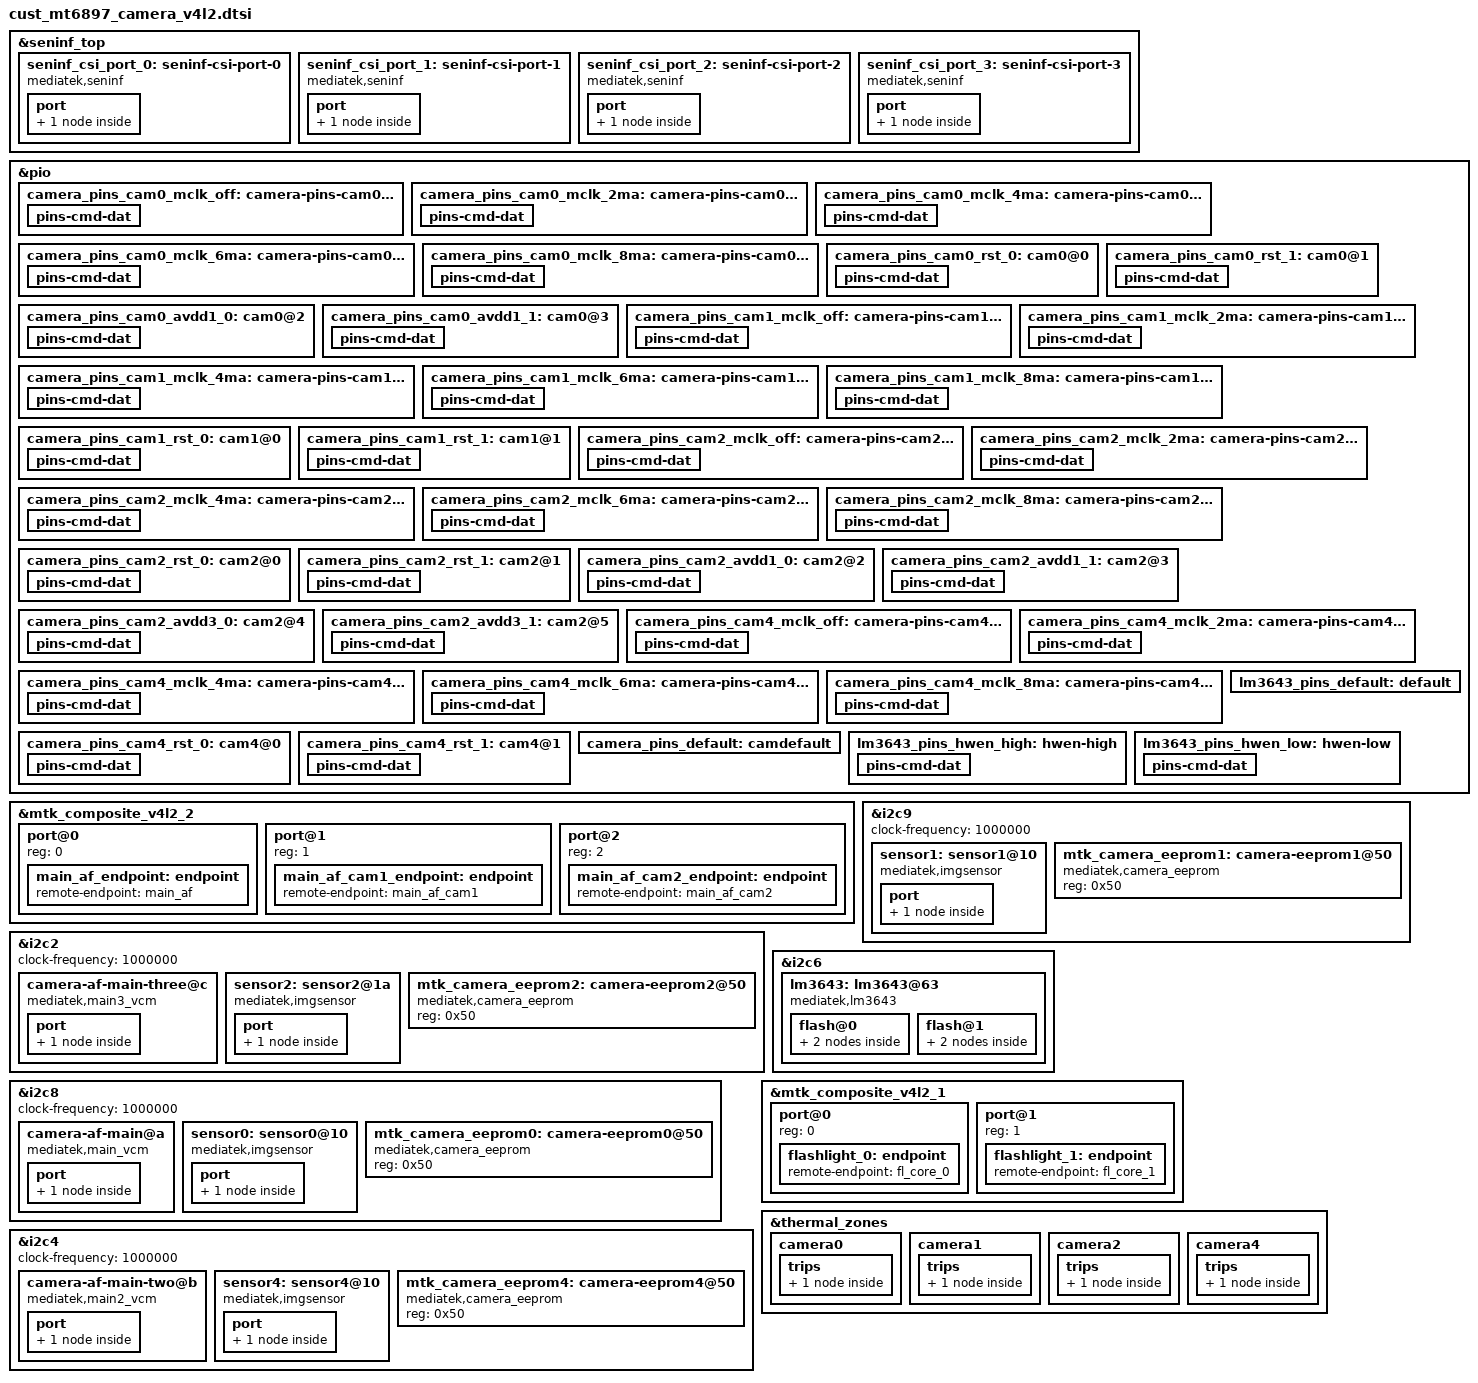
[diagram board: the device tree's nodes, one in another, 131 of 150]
// SPDX-License-Identifier: GPL-2.0
/* Copyright (c) 2020 MediaTek Inc. */
#include <dt-bindings/clock/mt6897-clk.h>


&seninf_top {
		seninf_csi_port_0: seninf-csi-port-0 {
			compatible = "mediatek,seninf";
			csi-port = "0";
			dphy-settle-delay-dt = <17>;
			nvmem-cells = <&csi_efuse0>;
			nvmem-cell-names = "rg_csi";
			port {
				seninf_csi_port_0_in: endpoint {
					remote-endpoint = <&sensor1_out>;
				};
			};
		};

		seninf_csi_port_1: seninf-csi-port-1 {
			compatible = "mediatek,seninf";
			csi-port = "1";
			hs-trail-parameter = <0x20>;
			nvmem-cells = <&csi_efuse1>;
			nvmem-cell-names = "rg_csi";
			port {
				seninf_csi_port_1_in: endpoint {
					remote-endpoint = <&sensor4_out>;
				};
			};
		};

		seninf_csi_port_2: seninf-csi-port-2 {
			compatible = "mediatek,seninf";
			csi-port = "2";
			hs-trail-parameter = <0x20>;
			nvmem-cells = <&csi_efuse2>;
			nvmem-cell-names = "rg_csi";
			port {
				seninf_csi_port_2_in: endpoint {
					remote-endpoint = <&sensor0_out>;
				};
			};
		};
		seninf_csi_port_3: seninf-csi-port-3 {
			compatible = "mediatek,seninf";
			csi-port = "3";
			nvmem-cells = <&csi_efuse3>;
			nvmem-cell-names = "rg_csi";
			port {
				seninf_csi_port_3_in: endpoint {
					remote-endpoint = <&sensor2_out>;
				};
			};
		};
};

/* CAMERA GPIO standardization */
&pio {
	camera_pins_cam0_mclk_off: camera-pins-cam0-mclk-off {
		pins-cmd-dat {
			pinmux = <PINMUX_GPIO125__FUNC_GPIO125>;
			drive-strength = <1>;
		};
	};
	camera_pins_cam0_mclk_2ma: camera-pins-cam0-mclk-2ma {
		pins-cmd-dat {
			pinmux = <PINMUX_GPIO125__FUNC_CMMCLK2>;
			drive-strength = <0>;
		};
	};
	camera_pins_cam0_mclk_4ma: camera-pins-cam0-mclk-4ma {
		pins-cmd-dat {
			pinmux = <PINMUX_GPIO125__FUNC_CMMCLK2>;
			drive-strength = <1>;
		};
	};
	camera_pins_cam0_mclk_6ma: camera-pins-cam0-mclk-6ma {
		pins-cmd-dat {
			pinmux = <PINMUX_GPIO125__FUNC_CMMCLK2>;
			drive-strength = <2>;
		};
	};
	camera_pins_cam0_mclk_8ma: camera-pins-cam0-mclk-8ma {
		pins-cmd-dat {
			pinmux = <PINMUX_GPIO125__FUNC_CMMCLK2>;
			drive-strength = <3>;
		};
	};
	camera_pins_cam0_rst_0: cam0@0 {
		pins-cmd-dat {
			pinmux = <PINMUX_GPIO117__FUNC_GPIO117>;
			slew-rate = <1>;
			output-low;
		};
	};
	camera_pins_cam0_rst_1: cam0@1 {
		pins-cmd-dat {
			pinmux = <PINMUX_GPIO117__FUNC_GPIO117>;
			slew-rate = <1>;
			output-high;
		};
	};
	camera_pins_cam0_avdd1_0: cam0@2 {
		pins-cmd-dat {
			pinmux = <PINMUX_GPIO160__FUNC_GPIO160>;
			slew-rate = <1>;
			output-low;
		};
	};
	camera_pins_cam0_avdd1_1: cam0@3 {
		pins-cmd-dat {
			pinmux = <PINMUX_GPIO160__FUNC_GPIO160>;
			slew-rate = <1>;
			output-high;
		};
	};
	camera_pins_cam1_mclk_off: camera-pins-cam1-mclk-off {
		pins-cmd-dat {
			pinmux = <PINMUX_GPIO126__FUNC_GPIO126>;
			drive-strength = <1>;
		};
	};
	camera_pins_cam1_mclk_2ma: camera-pins-cam1-mclk-2ma {
		pins-cmd-dat {
			pinmux = <PINMUX_GPIO126__FUNC_CMMCLK3>;
			drive-strength = <0>;
		};
	};
	camera_pins_cam1_mclk_4ma: camera-pins-cam1-mclk-4ma {
		pins-cmd-dat {
			pinmux = <PINMUX_GPIO126__FUNC_CMMCLK3>;
			drive-strength = <1>;
		};
	};
	camera_pins_cam1_mclk_6ma: camera-pins-cam1-mclk-6ma {
		pins-cmd-dat {
			pinmux = <PINMUX_GPIO126__FUNC_CMMCLK3>;
			drive-strength = <2>;
		};
	};
	camera_pins_cam1_mclk_8ma: camera-pins-cam1-mclk-8ma {
		pins-cmd-dat {
			pinmux = <PINMUX_GPIO126__FUNC_CMMCLK3>;
			drive-strength = <3>;
		};
	};
	camera_pins_cam1_rst_0: cam1@0 {
		pins-cmd-dat {
			pinmux = <PINMUX_GPIO118__FUNC_GPIO118>;
			slew-rate = <1>;
			output-low;
		};
	};
	camera_pins_cam1_rst_1: cam1@1 {
		pins-cmd-dat {
			pinmux = <PINMUX_GPIO118__FUNC_GPIO118>;
			slew-rate = <1>;
			output-high;
		};
	};
	camera_pins_cam2_mclk_off: camera-pins-cam2-mclk-off {
		pins-cmd-dat {
			pinmux = <PINMUX_GPIO127__FUNC_GPIO127>;
			drive-strength = <1>;
		};
	};
	camera_pins_cam2_mclk_2ma: camera-pins-cam2-mclk-2ma {
		pins-cmd-dat {
			pinmux = <PINMUX_GPIO127__FUNC_CMMCLK4>;
			drive-strength = <0>;
		};
	};
	camera_pins_cam2_mclk_4ma: camera-pins-cam2-mclk-4ma {
		pins-cmd-dat {
			pinmux = <PINMUX_GPIO127__FUNC_CMMCLK4>;
			drive-strength = <1>;
		};
	};
	camera_pins_cam2_mclk_6ma: camera-pins-cam2-mclk-6ma {
		pins-cmd-dat {
			pinmux = <PINMUX_GPIO127__FUNC_CMMCLK4>;
			drive-strength = <2>;
		};
	};
	camera_pins_cam2_mclk_8ma: camera-pins-cam2-mclk-8ma {
		pins-cmd-dat {
			pinmux = <PINMUX_GPIO127__FUNC_CMMCLK4>;
			drive-strength = <3>;
		};
	};
	camera_pins_cam2_rst_0: cam2@0 {
		pins-cmd-dat {
			pinmux = <PINMUX_GPIO115__FUNC_GPIO115>;
			slew-rate = <1>;
			output-low;
		};
	};
	camera_pins_cam2_rst_1: cam2@1 {
		pins-cmd-dat {
			pinmux = <PINMUX_GPIO115__FUNC_GPIO115>;
			slew-rate = <1>;
			output-high;
		};
	};
	camera_pins_cam2_avdd1_0: cam2@2 {
		pins-cmd-dat {
			pinmux = <PINMUX_GPIO120__FUNC_GPIO120>;
			slew-rate = <1>;
			output-low;
		};
	};

	camera_pins_cam2_avdd1_1: cam2@3 {
		pins-cmd-dat {
			pinmux = <PINMUX_GPIO120__FUNC_GPIO120>;
			slew-rate = <1>;
			output-high;
		};
	};

	camera_pins_cam2_avdd3_0: cam2@4 {
		pins-cmd-dat {
			pinmux = <PINMUX_GPIO134__FUNC_GPIO134>;
			slew-rate = <1>;
			output-low;
		};
	};
	camera_pins_cam2_avdd3_1: cam2@5 {
		pins-cmd-dat {
			pinmux = <PINMUX_GPIO134__FUNC_GPIO134>;
			slew-rate = <1>;
			output-high;
		};
	};

	camera_pins_cam4_mclk_off: camera-pins-cam4-mclk-off {
		pins-cmd-dat {
			pinmux = <PINMUX_GPIO124__FUNC_GPIO124>;
			drive-strength = <1>;
		};
	};
	camera_pins_cam4_mclk_2ma: camera-pins-cam4-mclk-2ma {
		pins-cmd-dat {
			pinmux = <PINMUX_GPIO124__FUNC_CMMCLK1>;
			drive-strength = <0>;
		};
	};
	camera_pins_cam4_mclk_4ma: camera-pins-cam4-mclk-4ma {
		pins-cmd-dat {
			pinmux = <PINMUX_GPIO124__FUNC_CMMCLK1>;
			drive-strength = <1>;
		};
	};
	camera_pins_cam4_mclk_6ma: camera-pins-cam4-mclk-6ma {
		pins-cmd-dat {
			pinmux = <PINMUX_GPIO124__FUNC_CMMCLK1>;
			drive-strength = <2>;
		};
	};
	camera_pins_cam4_mclk_8ma: camera-pins-cam4-mclk-8ma {
		pins-cmd-dat {
			pinmux = <PINMUX_GPIO124__FUNC_CMMCLK1>;
			drive-strength = <3>;
		};
	};
	camera_pins_cam4_rst_0: cam4@0 {
		pins-cmd-dat {
			pinmux = <PINMUX_GPIO116__FUNC_GPIO116>;
			slew-rate = <1>;
			output-low;
		};
	};
	camera_pins_cam4_rst_1: cam4@1 {
		pins-cmd-dat {
			pinmux = <PINMUX_GPIO116__FUNC_GPIO116>;
			slew-rate = <1>;
			output-high;
		};
	};
	camera_pins_default: camdefault {
	};
};
/* CAMERA GPIO end */

&mtk_composite_v4l2_2 {
	#address-cells = <1>;
	#size-cells = <0>;
	port@0 {
		reg = <0>;
		main_af_endpoint: endpoint {
			remote-endpoint = <&main_af>;
		};
	};
	port@1 {
		reg = <1>;
		main_af_cam1_endpoint: endpoint {
			remote-endpoint = <&main_af_cam1>;
		};
	};
	port@2 {
		reg = <2>;
		main_af_cam2_endpoint: endpoint {
			remote-endpoint = <&main_af_cam2>;
		};
	};
};

&i2c2 {
	status = "okay";
	clock-frequency = <1000000>;
	#address-cells = <1>;
	#size-cells = <0>;

	camera-af-main-three@c {
		compatible = "mediatek,main3_vcm";
		reg = <0x0c>;
		vin-supply = <&rt5133_gpio1>;
		port {
			main_af_cam2: endpoint {
				remote-endpoint = <&main_af_cam2_endpoint>;
			};
		};
	};

	sensor2: sensor2@1a {
		compatible = "mediatek,imgsensor";
		sensor-names = "imx766_mipi_raw",
				"imx709_mipi_raw",
				"imx866_mipi_raw",
				"imx598_mipi_raw";
		reg = <0x1a>;
		#thermal-sensor-cells = <0>;

		reindex-match = "imx766_mipi_raw",
				"imx709_mipi_raw",
				"imx866_mipi_raw";

		reindex-to = <0>;

		pinctrl-names = "mclk_off",
				"mclk_2mA",
				"mclk_4mA",
				"mclk_6mA",
				"mclk_8mA",
				"rst_low",
				"rst_high",
				"avdd1_off",
				"avdd1_on",
				"avdd3_off",
				"avdd3_on";
		pinctrl-0 = <&camera_pins_cam2_mclk_off>;
		pinctrl-1 = <&camera_pins_cam2_mclk_2ma>;
		pinctrl-2 = <&camera_pins_cam2_mclk_4ma>;
		pinctrl-3 = <&camera_pins_cam2_mclk_6ma>;
		pinctrl-4 = <&camera_pins_cam2_mclk_8ma>;
		pinctrl-5 = <&camera_pins_cam2_rst_0>;
		pinctrl-6 = <&camera_pins_cam2_rst_1>;
		pinctrl-7 = <&camera_pins_cam2_avdd1_0>; // AVDD2 for imx766
		pinctrl-8 = <&camera_pins_cam2_avdd1_1>; // AVDD2 for imx766
		pinctrl-9 = <&camera_pins_cam2_avdd3_0>; // AVDD2 for imx866
		pinctrl-10 = <&camera_pins_cam2_avdd3_1>; // AVDD2 for imx866

		avdd4-supply = <&rt5133_ldo5>; // AVDD2 for imx598
		avdd2-supply = <&rt5133_gpio2>; // AVDD for imx766 & imx866
		dvdd-supply = <&rt5133_ldo7>;
		dovdd-supply = <&rt5133_ldo1>;
		afvdd1-supply = <&rt5133_gpio1>;
		dvdd1-supply = <&rt5133_ldo8>;

		clocks = <&topckgen_clk CLK_TOP_UNIVPLL_192M_D32>,
			<&topckgen_clk CLK_TOP_UNIVPLL_192M_D16>,
			<&topckgen_clk CLK_TOP_F26M_CK_D2>,
			<&topckgen_clk CLK_TOP_UNIVPLL_192M_D10>,
			<&topckgen_clk CLK_TOP_UNIVPLL_192M_D8>,
			<&topckgen_clk CLK_TOP_UNIVPLL_D6_D16>,
			<&topckgen_clk CLK_TOP_UNIVPLL_D6_D8>,
			<&topckgen_clk CLK_TOP_CAMTG5_SEL>;
		clock-names = "6", "12", "13", "19.2", "24", "26", "52", "mclk";

		status = "okay";

		port {
			sensor2_out: endpoint {
				remote-endpoint = <&seninf_csi_port_3_in>;
			};
		};
	};

	mtk_camera_eeprom2:camera-eeprom2@50 {
		compatible = "mediatek,camera_eeprom";
		reg = <0x50>;
		status = "okay";
	};
};

&i2c9 {
	status = "okay";
	clock-frequency = <1000000>;
	#address-cells = <1>;
	#size-cells = <0>;

	sensor1: sensor1@10 {
		compatible = "mediatek,imgsensor";
		sensor-names = "s5k3p9sp_mipi_raw";
		reg = <0x10>;
		#thermal-sensor-cells = <0>;

		pinctrl-names = "mclk_off",
				"mclk_2mA",
				"mclk_4mA",
				"mclk_6mA",
				"mclk_8mA",
				"rst_low",
				"rst_high";
		pinctrl-0 = <&camera_pins_cam1_mclk_off>;
		pinctrl-1 = <&camera_pins_cam1_mclk_2ma>;
		pinctrl-2 = <&camera_pins_cam1_mclk_4ma>;
		pinctrl-3 = <&camera_pins_cam1_mclk_6ma>;
		pinctrl-4 = <&camera_pins_cam1_mclk_8ma>;
		pinctrl-5 = <&camera_pins_cam1_rst_0>;
		pinctrl-6 = <&camera_pins_cam1_rst_1>;

		avdd-supply = <&rt5133_ldo6>;
		dvdd-supply = <&rt5133_ldo7>;
		dovdd-supply = <&rt5133_ldo1>;
		afvdd-supply = <&rt5133_ldo2>;

		clocks = <&topckgen_clk CLK_TOP_UNIVPLL_192M_D32>,
			<&topckgen_clk CLK_TOP_UNIVPLL_192M_D16>,
			<&topckgen_clk CLK_TOP_F26M_CK_D2>,
			<&topckgen_clk CLK_TOP_UNIVPLL_192M_D10>,
			<&topckgen_clk CLK_TOP_UNIVPLL_192M_D8>,
			<&topckgen_clk CLK_TOP_UNIVPLL_D6_D16>,
			<&topckgen_clk CLK_TOP_UNIVPLL_D6_D8>,
			<&topckgen_clk CLK_TOP_CAMTG4_SEL>;
		clock-names = "6", "12", "13", "19.2", "24", "26", "52", "mclk";

		status = "okay";

		port {
			sensor1_out: endpoint {
				remote-endpoint = <&seninf_csi_port_0_in>;
			};
		};
	};

	mtk_camera_eeprom1:camera-eeprom1@50 {
		compatible = "mediatek,camera_eeprom";
		reg = <0x50>;
		status = "okay";
	};
};

&i2c8 {
	status = "okay";
	clock-frequency = <1000000>;
	#address-cells = <1>;
	#size-cells = <0>;

	camera-af-main@a {
		compatible = "mediatek,main_vcm";
		reg = <0x0a>;
		vin-supply = <&rt5133_ldo3>;
		port {
			main_af: endpoint {
				remote-endpoint = <&main_af_endpoint>;
			};
		};
	};

	sensor0: sensor0@10 {
		compatible = "mediatek,imgsensor";
		sensor-names = "ov48b_mipi_raw",
				"ov64b_mipi_raw",
				"imx766dual_mipi_raw",
				"imx989_mipi_raw",
				"imx758_mipi_raw",
				"imx519_mipi_raw",
				"imx499_mipi_raw";
		reg = <0x10>;
		#thermal-sensor-cells = <0>;

		/* reindex sensor if match sensor list */
		reindex-match = "imx766dual_mipi_raw";

		reindex-to = <2>;

		pinctrl-names = "mclk_off",
				"mclk_2mA",
				"mclk_4mA",
				"mclk_6mA",
				"mclk_8mA",
				"rst_low",
				"rst_high",
				"avdd1_off",
				"avdd1_on";
		pinctrl-0 = <&camera_pins_cam0_mclk_off>;
		pinctrl-1 = <&camera_pins_cam0_mclk_2ma>;
		pinctrl-2 = <&camera_pins_cam0_mclk_4ma>;
		pinctrl-3 = <&camera_pins_cam0_mclk_6ma>;
		pinctrl-4 = <&camera_pins_cam0_mclk_8ma>;
		pinctrl-5 = <&camera_pins_cam0_rst_0>;
		pinctrl-6 = <&camera_pins_cam0_rst_1>;
		pinctrl-7 = <&camera_pins_cam0_avdd1_0>;
		pinctrl-8 = <&camera_pins_cam0_avdd1_1>;

		avdd-supply = <&rt5133_ldo4>;
		avdd2-supply = <&rt5133_ldo5>;
		dvdd-supply = <&rt5133_ldo8>;
		dovdd-supply = <&rt5133_ldo1>;
		afvdd-supply = <&rt5133_ldo3>;

		clocks = <&topckgen_clk CLK_TOP_UNIVPLL_192M_D32>,
			<&topckgen_clk CLK_TOP_UNIVPLL_192M_D16>,
			<&topckgen_clk CLK_TOP_F26M_CK_D2>,
			<&topckgen_clk CLK_TOP_UNIVPLL_192M_D10>,
			<&topckgen_clk CLK_TOP_UNIVPLL_192M_D8>,
			<&topckgen_clk CLK_TOP_UNIVPLL_D6_D16>,
			<&topckgen_clk CLK_TOP_UNIVPLL_D6_D8>,
			<&topckgen_clk CLK_TOP_CAMTG3_SEL>;
		clock-names = "6", "12", "13", "19.2", "24", "26", "52", "mclk";

		status = "okay";

		port {
			sensor0_out: endpoint {
				remote-endpoint = <&seninf_csi_port_2_in>;
			};
		};
	};

	mtk_camera_eeprom0:camera-eeprom0@50 {
		compatible = "mediatek,camera_eeprom";
		reg = <0x50>;
		status = "okay";
	};
};

&i2c4 {
	status = "okay";
	clock-frequency = <1000000>;
	#address-cells = <1>;
	#size-cells = <0>;

	camera-af-main-two@b {
		compatible = "mediatek,main2_vcm";
		reg = <0x0b>;
		vin-supply = <&rt5133_ldo2>;
		port {
			main_af_cam1: endpoint {
				remote-endpoint = <&main_af_cam1_endpoint>;
			};
		};
	};

	sensor4: sensor4@10 {
		compatible = "mediatek,imgsensor";
		sensor-names = "s5k3m5sx_mipi_raw";
		reg = <0x10>;
		#thermal-sensor-cells = <0>;
		pinctrl-names = "mclk_off",
				"mclk_2mA",
				"mclk_4mA",
				"mclk_6mA",
				"mclk_8mA",
				"rst_low",
				"rst_high";
		pinctrl-0 = <&camera_pins_cam4_mclk_off>;
		pinctrl-1 = <&camera_pins_cam4_mclk_2ma>;
		pinctrl-2 = <&camera_pins_cam4_mclk_4ma>;
		pinctrl-3 = <&camera_pins_cam4_mclk_6ma>;
		pinctrl-4 = <&camera_pins_cam4_mclk_8ma>;
		pinctrl-5 = <&camera_pins_cam4_rst_0>;
		pinctrl-6 = <&camera_pins_cam4_rst_1>;

		avdd-supply = <&rt5133_ldo6>;
		dvdd-supply = <&rt5133_gpio3>;
		dovdd-supply = <&rt5133_ldo1>;
		afvdd-supply = <&rt5133_ldo2>;

		clocks = <&topckgen_clk CLK_TOP_UNIVPLL_192M_D32>,
			<&topckgen_clk CLK_TOP_UNIVPLL_192M_D16>,
			<&topckgen_clk CLK_TOP_F26M_CK_D2>,
			<&topckgen_clk CLK_TOP_UNIVPLL_192M_D10>,
			<&topckgen_clk CLK_TOP_UNIVPLL_192M_D8>,
			<&topckgen_clk CLK_TOP_UNIVPLL_D6_D16>,
			<&topckgen_clk CLK_TOP_UNIVPLL_D6_D8>,
			<&topckgen_clk CLK_TOP_CAMTG2_SEL>;
		clock-names = "6", "12", "13", "19.2", "24", "26", "52", "mclk";

		status = "okay";

		port {
			sensor4_out: endpoint {
				remote-endpoint = <&seninf_csi_port_1_in>;
			};
		};
	};

	mtk_camera_eeprom4:camera-eeprom4@50 {
		compatible = "mediatek,camera_eeprom";
		reg = <0x50>;
		status = "okay";
	};
};

&i2c6 {
	#address-cells = <1>;
	#size-cells = <0>;
	lm3643:lm3643@63 {
		compatible = "mediatek,lm3643";
		#address-cells = <1>;
		#size-cells = <0>;
		reg = <0x63>;
		#cooling-cells = <2>;
		pinctrl-names = "default", "hwen-high", "hwen-low";
		pinctrl-0 = <&lm3643_pins_default>;
		pinctrl-1 = <&lm3643_pins_hwen_high>;
		pinctrl-2 = <&lm3643_pins_hwen_low>;
		status = "okay";
		flash@0{
			reg = <0>;
			type = <0>;
			ct = <0>;
			part = <0>;
			port {
				fl_core_0: endpoint {
					remote-endpoint = <&flashlight_0>;
				};
			};
		};
		flash@1{
			reg = <1>;
			type = <0>;
			ct = <1>;
			part = <0>;
			port {
				fl_core_1: endpoint {
					remote-endpoint = <&flashlight_1>;
				};
			};
		};
	};
};

&pio {
	lm3643_pins_default: default {
	};

	lm3643_pins_hwen_high: hwen-high {
		pins-cmd-dat {
			pinmux = <PINMUX_GPIO62__FUNC_GPIO62>;
			slew-rate = <1>;
			output-high;
		};
	};

	lm3643_pins_hwen_low: hwen-low {
		pins-cmd-dat {
			pinmux = <PINMUX_GPIO62__FUNC_GPIO62>;
			slew-rate = <1>;
			output-low;
		};
	};
};

&mtk_composite_v4l2_1 {
	#address-cells = <1>;
	#size-cells = <0>;
	port@0 {
		reg = <0>;
		flashlight_0: endpoint {
			remote-endpoint = <&fl_core_0>;
		};
	};
	port@1 {
		reg = <1>;
		flashlight_1: endpoint {
			remote-endpoint = <&fl_core_1>;
		};
	};
};


&thermal_zones {
	camera0: camera0 {
		polling-delay = <0>; /* milliseconds */
		polling-delay-passive = <0>; /* milliseconds */
		thermal-sensors = <&sensor0>;
		trips {
			camera0_crit: camera0-crit {
				temperature = <120000>;
				hysteresis = <2000>;
				type = "passive";
			};
		};
	};
	camera1: camera1 {
		polling-delay = <0>; /* milliseconds */
		polling-delay-passive = <0>; /* milliseconds */
		thermal-sensors = <&sensor1>;
		trips {
			camera1_crit: camera1-crit {
				temperature = <120000>;
				hysteresis = <2000>;
				type = "passive";
			};
		};
	};
	camera2: camera2 {
		polling-delay = <0>; /* milliseconds */
		polling-delay-passive = <0>; /* milliseconds */
		thermal-sensors = <&sensor2>;
		trips {
			camera2_crit: camera2-crit {
				temperature = <120000>;
				hysteresis = <2000>;
				type = "passive";
			};
		};
	};
	camera4: camera4 {
		polling-delay = <0>; /* milliseconds */
		polling-delay-passive = <0>; /* milliseconds */
		thermal-sensors = <&sensor4>;
		trips {
			camera4_crit: camera4-crit {
				temperature = <120000>;
				hysteresis = <2000>;
				type = "passive";
			};
		};
	};
};
